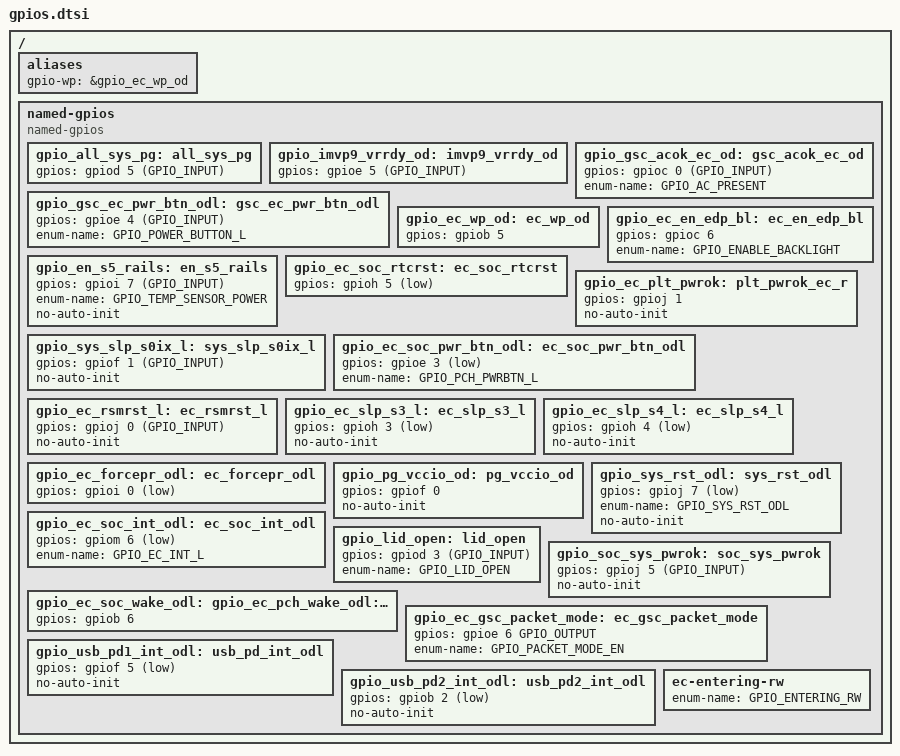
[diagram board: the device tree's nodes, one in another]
/* Copyright 2026 The ChromiumOS Authors
 * Use of this source code is governed by a BSD-style license that can be
 * found in the LICENSE file.
 */

/ {
	aliases {
		gpio-wp = &gpio_ec_wp_od;
	};

	named-gpios {
		compatible = "named-gpios";

		gpio_all_sys_pg: all_sys_pg {
			gpios = <&gpiod 5 (GPIO_INPUT)>;
		};
		gpio_imvp9_vrrdy_od: imvp9_vrrdy_od {
			gpios = <&gpioe 5 (GPIO_INPUT)>;
		};
		gpio_gsc_ec_pwr_btn_odl: gsc_ec_pwr_btn_odl {
			gpios = <&gpioe 4 (GPIO_INPUT)>;
			enum-name = "GPIO_POWER_BUTTON_L";
		};
		gpio_gsc_acok_ec_od: gsc_acok_ec_od {
			gpios = <&gpioc 0 (GPIO_INPUT)>;
			enum-name = "GPIO_AC_PRESENT";
		};
		gpio_ec_wp_od: ec_wp_od {
			gpios = <&gpiob 5 (GPIO_INPUT | GPIO_ACTIVE_HIGH)>;
		};
		gpio_ec_en_edp_bl: ec_en_edp_bl {
			gpios = <&gpioc 6 (GPIO_OUTPUT | GPIO_ACTIVE_HIGH | GPIO_OUTPUT_INIT_HIGH)>;
			enum-name = "GPIO_ENABLE_BACKLIGHT";
		};
		gpio_en_s5_rails: en_s5_rails {
			gpios = <&gpioi 7 (GPIO_INPUT)>;
			enum-name = "GPIO_TEMP_SENSOR_POWER";
			no-auto-init;
		};
		gpio_ec_soc_rtcrst: ec_soc_rtcrst {
			gpios = <&gpioh 5 (GPIO_INPUT | GPIO_ACTIVE_LOW)>;
		};
		gpio_ec_plt_pwrok: plt_pwrok_ec_r {
			gpios = <&gpioj 1 (GPIO_OUTPUT | GPIO_ACTIVE_HIGH | GPIO_OUTPUT_INIT_LOW)>;
			no-auto-init;
		};
		gpio_sys_slp_s0ix_l: sys_slp_s0ix_l {
			gpios = <&gpiof 1 (GPIO_INPUT)>;
			no-auto-init;
		};
		gpio_ec_soc_pwr_btn_odl: ec_soc_pwr_btn_odl {
			gpios = <&gpioe 3 (GPIO_OUTPUT | GPIO_OPEN_DRAIN | GPIO_ACTIVE_LOW)>;
			enum-name = "GPIO_PCH_PWRBTN_L";
		};
		gpio_ec_rsmrst_l: ec_rsmrst_l {
			gpios = <&gpioj 0 (GPIO_INPUT)>;
			no-auto-init;
		};
		gpio_ec_slp_s3_l: ec_slp_s3_l {
			gpios = <&gpioh 3 (GPIO_INPUT | GPIO_ACTIVE_LOW)>;
			no-auto-init;
		};
		gpio_ec_slp_s4_l: ec_slp_s4_l {
			gpios = <&gpioh 4 (GPIO_INPUT | GPIO_ACTIVE_LOW)>;
			no-auto-init;
		};
		gpio_ec_forcepr_odl: ec_forcepr_odl {
			gpios = <&gpioi 0 (GPIO_INPUT | GPIO_ACTIVE_LOW)>;
		};
		gpio_pg_vccio_od: pg_vccio_od {
			gpios = <&gpiof 0 (GPIO_INPUT | GPIO_VOLTAGE_1P8)>;
			no-auto-init;
		};
		gpio_sys_rst_odl: sys_rst_odl {
			gpios = <&gpioj 7 (GPIO_OUTPUT | GPIO_OPEN_DRAIN | GPIO_ACTIVE_LOW | GPIO_OUTPUT_INIT_HIGH)>;
			enum-name = "GPIO_SYS_RST_ODL";
			no-auto-init;
		};
		gpio_ec_soc_int_odl: ec_soc_int_odl {
			gpios = <&gpiom 6 (GPIO_OUTPUT | GPIO_OPEN_DRAIN | GPIO_ACTIVE_LOW)>;
			enum-name = "GPIO_EC_INT_L";
		};
		gpio_lid_open: lid_open {
			gpios = <&gpiod 3 (GPIO_INPUT)>;
			enum-name = "GPIO_LID_OPEN";
		};
		gpio_ec_soc_wake_odl: ec_soc_wake_odl {
			gpios = <&gpiob 6 (GPIO_OUTPUT | GPIO_OPEN_DRAIN | GPIO_ACTIVE_HIGH | GPIO_OUTPUT_INIT_HIGH)>;
		};
		gpio_soc_sys_pwrok: soc_sys_pwrok {
			gpios = <&gpioj 5 (GPIO_INPUT)>;
			no-auto-init;
		};
		gpio_ec_gsc_packet_mode: ec_gsc_packet_mode {
			gpios = <&gpioe 6 GPIO_OUTPUT>;
			enum-name = "GPIO_PACKET_MODE_EN";
		};
		gpio_usb_pd1_int_odl: usb_pd_int_odl {
			gpios = <&gpiof 5 (GPIO_INPUT | GPIO_ACTIVE_LOW)>;
			no-auto-init;
		};
		gpio_usb_pd2_int_odl: usb_pd2_int_odl {
			gpios = <&gpiob 2 (GPIO_INPUT | GPIO_ACTIVE_LOW)>;
			no-auto-init;
		};
		/* The legacy system code requires GPIO_ENTERING_RW symbol */
		ec-entering-rw {
			enum-name = "GPIO_ENTERING_RW";
		};
	};
};

/* The eSPI shim requires this GPIO nodelabel */
gpio_ec_pch_wake_odl: &gpio_ec_soc_wake_odl {};
